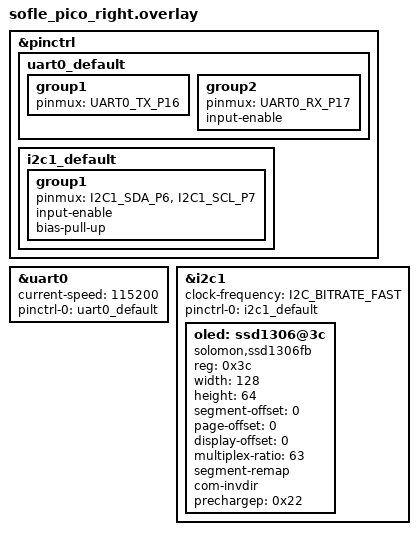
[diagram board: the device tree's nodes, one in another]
#include <zephyr/dt-bindings/gpio/gpio.h>
#include <dt-bindings/pinctrl/rpi-pico-rp2040-pinctrl.h>

&pinctrl {
    uart0_default: uart0_default {
        group1 {
            pinmux = <UART0_TX_P16>;
        };
        group2 {
            pinmux = <UART0_RX_P17>;
            input-enable;
        };
    };

    i2c1_default: i2c1_default {
        group1 {
            pinmux = <I2C1_SDA_P6>, <I2C1_SCL_P7>;
            input-enable;
            bias-pull-up;
        };
    };
};

&uart0 {
    status = "okay";
    current-speed = <115200>;
    pinctrl-0 = <&uart0_default>;
    pinctrl-names = "default";
};

&i2c1 {
    status = "okay";
    clock-frequency = <I2C_BITRATE_FAST>;
    pinctrl-0 = <&i2c1_default>;
    pinctrl-names = "default";

    oled: ssd1306@3c {
        compatible = "solomon,ssd1306fb";
        reg = <0x3c>;
        width = <128>;
        height = <64>;
        segment-offset = <0>;
        page-offset = <0>;
        display-offset = <0>;
        multiplex-ratio = <63>;
        segment-remap;
        com-invdir;
        prechargep = <0x22>;
    };
};
